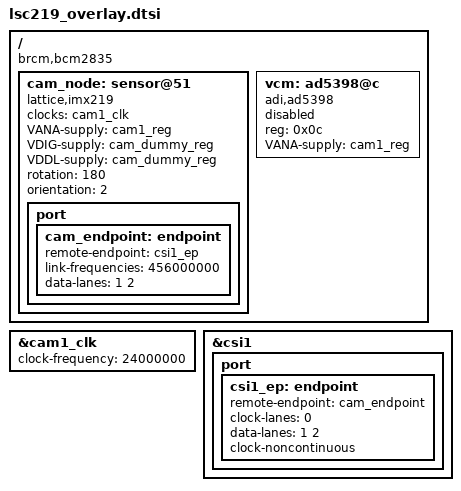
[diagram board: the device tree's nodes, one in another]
// SPDX-License-Identifier: GPL-2.0-only
// Definitions for LSC219 camera module on CSI0
/dts-v1/;
/plugin/;

/{
	compatible = "brcm,bcm2835";

	clk_frag: fragment@1 {
		target = <&cam1_clk>;
		__overlay__ {
			status = "okay";
			clock-frequency = <24000000>;
		};
	};

	fragment@100 {
		target-path = "/";
		__overlay__ {
                // Address @51 is used as reference to lattice HUB Gard
                // Not used as i2c address overlaying.
			cam_node: sensor@51 {
				compatible = "lattice,imx219";
				status = "okay";

				clocks = <&cam1_clk>;
				clock-names = "xclk";

				VANA-supply = <&cam1_reg>;	/* 2.8v */
				VDIG-supply = <&cam_dummy_reg>;	/* 1.8v */
				VDDL-supply = <&cam_dummy_reg>;	/* 1.2v */

				rotation = <180>;
				orientation = <2>;

				port {
					cam_endpoint: endpoint {
						remote-endpoint = <&csi1_ep>;
						link-frequencies =
						/bits/ 64 <456000000>;
					};
				};
			};

			vcm: ad5398@c {
				compatible = "adi,ad5398";
				reg = <0x0c>;
				status = "disabled";
				VANA-supply = <&cam1_reg>;
			};
		};
	};

	csi_frag: fragment@101 {
		target = <&csi1>;
		__overlay__ {
			status = "okay";

			port {
				csi1_ep: endpoint {
					remote-endpoint = <&cam_endpoint>;
					clock-lanes = <0>;
					data-lanes = <1 2>;
					clock-noncontinuous;
				};
			};
		};
	};

	fragment@103 {
		target = <&csi1_ep>;
		__overlay__ {
			data-lanes = <1 2>;
		};
	};

	fragment@104 {
		target = <&csi1_ep>;
		__dormant__ {
			data-lanes = <1 2 3 4>;
		};
	};

	fragment@106 {
		target = <&cam_endpoint>;
		__overlay__ {
			data-lanes = <1 2>;
		};
	};

	fragment@107 {
		target = <&cam_endpoint>;
		__dormant__ {
			data-lanes = <1 2 3 4>;
			link-frequencies =
					/bits/ 64 <364000000>;
		};
	};

	__overrides__ {
		rotation = <&cam_node>,"rotation:0";
		orientation = <&cam_node>,"orientation:0";
		media-controller = <0>,"!102";
		cam0 = <&csi_frag>, "target:0=",<&csi0>,
			   <&clk_frag>, "target:0=",<&cam0_clk>,
			   <&cam_node>, "clocks:0=",<&cam0_clk>,
			   <&cam_node>, "VANA-supply:0=",<&cam0_reg>,
		       <&vcm>, "VANA-supply:0=", <&cam0_reg>;
		vcm = <&vcm>, "status=okay",
			  <&cam_node>,"lens-focus:0=", <&vcm>;
                // when 4lane is configured in overlay
                // fragment 104 and 107 is activated.
		4lane = <0>, "+104+107";
	};
};
